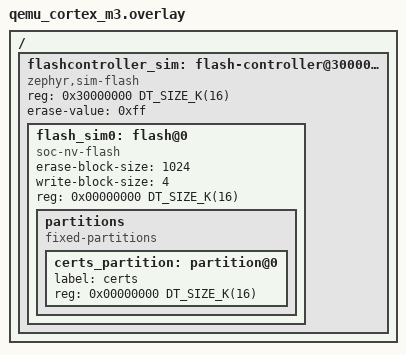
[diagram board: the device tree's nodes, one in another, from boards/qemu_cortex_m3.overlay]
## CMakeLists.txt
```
cmake_minimum_required(VERSION 3.20.0)
list(PREPEND ZEPHYR_EXTRA_MODULES "${CMAKE_CURRENT_SOURCE_DIR}/../..")
find_package(Zephyr REQUIRED HINTS $ENV{ZEPHYR_BASE})
project(zplc_tls_credentials)

target_sources(app PRIVATE
  src/main.c
  ${CMAKE_CURRENT_SOURCE_DIR}/../../app/src/zplc_tls_credentials.c
)
target_include_directories(app PRIVATE
  ${CMAKE_CURRENT_SOURCE_DIR}/../../app/src
  ${CMAKE_CURRENT_SOURCE_DIR}/../../app/include
  ${CMAKE_CURRENT_SOURCE_DIR}/../../lib/zplc_core/include
)

# The files of the runtime compiled into this application are optimized across files as the product's are
# (CONFIG_ZPLC_LTO), so that the suite exercises the code that ships.
if(COMMAND zplc_target_lto)
  zplc_target_lto(app)
endif()
```

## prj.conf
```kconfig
CONFIG_ZTEST=y
CONFIG_ASSERT=y
CONFIG_LOG=n
CONFIG_PRINTK=n
CONFIG_FILE_SYSTEM=y
CONFIG_FILE_SYSTEM_MKFS=y
CONFIG_FILE_SYSTEM_LITTLEFS=y
CONFIG_FLASH=y
CONFIG_FLASH_MAP=y
CONFIG_NETWORKING=y
CONFIG_NET_SOCKETS=y
CONFIG_TLS_CREDENTIALS=y
```

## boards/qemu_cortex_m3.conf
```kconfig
CONFIG_FLASH_SIMULATOR=y
CONFIG_ZTEST_STACK_SIZE=4096
# The network stack is linked for the credential API only. No interface is
# brought up, so QEMU needs no SLIP socket and the entropy source is the test
# generator the stack asks for.
CONFIG_NET_SLIP_TAP=n
CONFIG_TEST_RANDOM_GENERATOR=y
```

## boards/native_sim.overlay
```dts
&flashcontroller0 {
    reg = <0x00000000 DT_SIZE_K(64)>;
};

&flash0 {
    reg = <0x00000000 DT_SIZE_K(64)>;

    partitions {
        compatible = "fixed-partitions";
        #address-cells = <1>;
        #size-cells = <1>;

        certs_partition: partition@0 {
            label = "certs";
            reg = <0x00000000 DT_SIZE_K(64)>;
        };
    };
};
```

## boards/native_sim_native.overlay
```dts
/* Zephyr selects board overlays by exact qualifier: native_sim/native (32-bit)
 * does not read native_sim_native_64.overlay. One source of truth, two names. */
#include "native_sim_native_64.overlay"
```

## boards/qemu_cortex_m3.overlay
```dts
/*
 * The lm3s6965 flash has no driver under QEMU, so the credential store runs
 * on a flash simulator held in RAM (a few KB of the 64 KB the board has).
 */
#include <mem.h>

/ {
	flashcontroller_sim: flash-controller@30000000 {
		compatible = "zephyr,sim-flash";
		reg = <0x30000000 DT_SIZE_K(16)>;
		#address-cells = <1>;
		#size-cells = <1>;
		erase-value = <0xff>;

		flash_sim0: flash@0 {
			compatible = "soc-nv-flash";
			erase-block-size = <1024>;
			write-block-size = <4>;
			reg = <0x00000000 DT_SIZE_K(16)>;

			partitions {
				compatible = "fixed-partitions";
				#address-cells = <1>;
				#size-cells = <1>;

				certs_partition: partition@0 {
					label = "certs";
					reg = <0x00000000 DT_SIZE_K(16)>;
				};
			};
		};
	};
};
```

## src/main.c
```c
#include <errno.h>
#include <string.h>

#include <zephyr/fs/fs.h>
#include <zephyr/fs/littlefs.h>
#include <zephyr/net/tls_credentials.h>
#include <zephyr/storage/flash_map.h>
#include <zephyr/ztest.h>

#include <zplc_hal.h>
#include "zplc_tls_credentials.h"

#define CERTS_PARTITION certs_partition

FS_LITTLEFS_DECLARE_DEFAULT_CONFIG(certs);

static struct fs_mount_t certs_mount = {
    .type = FS_LITTLEFS,
    .fs_data = &certs,
    .storage_dev = (void *)PARTITION_ID(CERTS_PARTITION),
    .mnt_point = "/certs",
};

/* A store that answers every key, as the HAL does for every record it has an identifier for (the program, the
 * settings keys, the keys of the device link): what the reader asks for is what the tests below look at. */
static unsigned int persist_loads;

zplc_hal_result_t zplc_hal_persist_load(const char *key, void *data, size_t len) {
  static const char value[] = "stored";

  persist_loads++;
  if (key != NULL && len >= sizeof(value)) {
    memcpy(data, value, sizeof(value));
    return ZPLC_HAL_OK;
  }
  return ZPLC_HAL_NOT_IMPL;
}

static void write_file(const char *path, const uint8_t *data, size_t len) {
  struct fs_file_t file;
  int rc;

  rc = fs_unlink(path);
  zassert_true(rc == 0 || rc == -ENOENT, "unlink %s", path);
  fs_file_t_init(&file);
  zassert_ok(fs_open(&file, path, FS_O_CREATE | FS_O_WRITE), "open %s", path);
  zassert_equal(fs_write(&file, data, len), len, "write %s", path);
  zassert_ok(fs_close(&file), "close %s", path);
}

static void *tls_credentials_setup(void) {
  const struct flash_area *area;
  const uintptr_t device_id = (uintptr_t)certs_mount.storage_dev;

  zassert_ok(flash_area_open(device_id, &area), "open certs flash");
  zassert_ok(flash_area_flatten(area, 0, area->fa_size), "erase certs flash");
  flash_area_close(area);
  zassert_ok(fs_mkfs(FS_LITTLEFS, device_id, certs_mount.fs_data, 0), "format certs");
  zassert_ok(fs_mount(&certs_mount), "mount certs");

  return NULL;
}

static void tls_credentials_teardown(void *fixture) {
  ARG_UNUSED(fixture);
  zassert_ok(fs_unmount(&certs_mount), "unmount certs");
}

ZTEST(tls_credentials, test_reader_rejects_stale_and_truncated_files) {
  const uint8_t exact[] = "1234567";
  const uint8_t too_big[] = "12345678";
  uint8_t out[8];

  write_file("/certs/exact.pem", exact, sizeof(exact) - 1U);
  memset(out, 0xA5, sizeof(out));
  zassert_equal(zplc_tls_credential_read_pem("/certs/exact.pem", out, sizeof(out)), 7, "cap-1 must fit");
  zassert_mem_equal(out, exact, sizeof(exact) - 1U, "exact bytes");
  zassert_equal(out[7], '\0', "terminated");

  write_file("/certs/too-big.pem", too_big, sizeof(too_big) - 1U);
  memset(out, 0xA5, sizeof(out));
  zassert_equal(zplc_tls_credential_read_pem("/certs/too-big.pem", out, sizeof(out)), -EFBIG, "cap must fail");
  zassert_mem_equal(out, (uint8_t[8]){0}, sizeof(out), "failed output cleared");

  write_file("/certs/empty.pem", NULL, 0U);
  memset(out, 0xA5, sizeof(out));
  zassert_true(zplc_tls_credential_read_pem("/certs/empty.pem", out, sizeof(out)) < 0, "empty must fail");
  zassert_mem_equal(out, (uint8_t[8]){0}, sizeof(out), "empty output cleared");
}

ZTEST(tls_credentials, test_replace_replaces_long_credential_exactly) {
  static const uint8_t long_value[] = "long credential";
  static const uint8_t short_value[] = "short";
  uint8_t credential[sizeof(short_value)];
  size_t credential_len = sizeof(credential);
  const sec_tag_t tag = 4811;

  zassert_equal(tls_credential_delete(tag, TLS_CREDENTIAL_CA_CERTIFICATE), -ENOENT, "must start absent");
  zassert_ok(zplc_tls_credential_replace(tag, TLS_CREDENTIAL_CA_CERTIFICATE, long_value, sizeof(long_value)), "install long");
  zassert_ok(zplc_tls_credential_replace(tag, TLS_CREDENTIAL_CA_CERTIFICATE, short_value, sizeof(short_value)), "replace short");
  zassert_ok(tls_credential_get(tag, TLS_CREDENTIAL_CA_CERTIFICATE, credential, &credential_len), "get short");
  zassert_equal(credential_len, sizeof(short_value), "no stale suffix");
  zassert_mem_equal(credential, short_value, sizeof(short_value), "exact short bytes");
  zassert_ok(tls_credential_delete(tag, TLS_CREDENTIAL_CA_CERTIFICATE), "cleanup");
}

ZTEST(tls_credentials, test_persisted_reader_requires_a_nonempty_key) {
  uint8_t out[8];

  memset(out, 0xA5, sizeof(out));
  zassert_equal(zplc_tls_credential_read_pem("persist://aws_cert_pem", out, sizeof(out)), 6, "persisted PEM");
  zassert_str_equal((char *)out, "stored", "persisted bytes");
  memset(out, 0xA5, sizeof(out));
  zassert_equal(zplc_tls_credential_read_pem("persist://aws_key_pem", out, sizeof(out)), 6, "persisted key PEM");
  memset(out, 0xA5, sizeof(out));
  zassert_equal(zplc_tls_credential_read_pem("persist://", out, sizeof(out)), -EINVAL, "empty key");
  zassert_mem_equal(out, (uint8_t[8]){0}, sizeof(out), "empty key clears output");
}

/* ---- IO-008: a persist:// name that is not a credential record is refused, never read as PEM ---- */
ZTEST(tls_credentials, test_persisted_reader_refuses_records_that_are_not_credentials) {
  static const char *const refused[] = {
      "persist://link_key",  "persist://link_signkey",      "persist://code", "persist://code_len",      "persist://cfg_07",
      "persist://retain_a0", "persist://program_v1_active", "persist://pem",  "persist://aws_cert_pem_", "persist://AWS_CERT_PEM",
  };
  uint8_t out[8];
  unsigned int loads;
  size_t index;

  for (index = 0U; index < ARRAY_SIZE(refused); index++) {
    memset(out, 0xA5, sizeof(out));
    loads = persist_loads;
    zassert_equal(zplc_tls_credential_read_pem(refused[index], out, sizeof(out)), -EACCES, "%s is refused", refused[index]);
    zassert_equal(persist_loads, loads, "%s is never read from the store", refused[index]);
    zassert_mem_equal(out, (uint8_t[8]){0}, sizeof(out), "%s leaves no bytes", refused[index]);
  }
}

ZTEST_SUITE(tls_credentials, NULL, tls_credentials_setup, NULL, NULL, tls_credentials_teardown);
```
